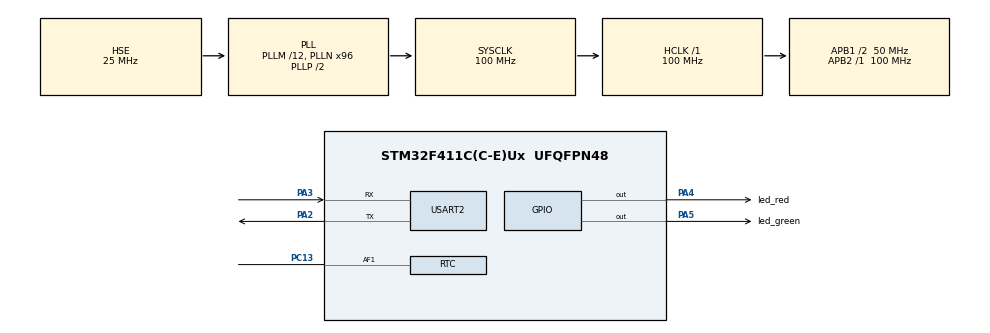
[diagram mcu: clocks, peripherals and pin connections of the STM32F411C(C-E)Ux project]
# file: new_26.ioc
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Dma.Request0=USART2_RX
Dma.Request1=USART2_TX
Dma.USART2_RX.0.Direction=DMA_PERIPH_TO_MEMORY
Dma.USART2_RX.0.FIFOMode=DMA_FIFOMODE_DISABLE
Dma.USART2_RX.0.Instance=DMA1_Stream5
Dma.USART2_RX.0.MemDataAlignment=DMA_MDATAALIGN_BYTE
Dma.USART2_RX.0.MemInc=DMA_MINC_ENABLE
Dma.USART2_RX.0.Mode=DMA_CIRCULAR
Dma.USART2_RX.0.PeriphDataAlignment=DMA_PDATAALIGN_BYTE
Dma.USART2_RX.0.PeriphInc=DMA_PINC_DISABLE
Dma.USART2_RX.0.Priority=DMA_PRIORITY_MEDIUM
Dma.USART2_TX.1.Direction=DMA_MEMORY_TO_PERIPH
Dma.USART2_TX.1.FIFOMode=DMA_FIFOMODE_DISABLE
Dma.USART2_TX.1.Instance=DMA1_Stream6
Dma.USART2_TX.1.MemDataAlignment=DMA_MDATAALIGN_BYTE
Dma.USART2_TX.1.MemInc=DMA_MINC_ENABLE
Dma.USART2_TX.1.Mode=DMA_NORMAL
Dma.USART2_TX.1.PeriphDataAlignment=DMA_PDATAALIGN_BYTE
Dma.USART2_TX.1.PeriphInc=DMA_PINC_DISABLE
Dma.USART2_TX.1.Priority=DMA_PRIORITY_LOW
FREERTOS.Queues01=queue_input_uart,10,uint16_t,0,Dynamic,NULL,NULL;queue_uart_output,10,uint16_t,0,Dynamic,NULL,NULL;queue_output_input,10,uint16_t,0,Dynamic,NULL,NULL
FREERTOS.Tasks01=task_input,24,128,start_task_input,Default,NULL,Dynamic,NULL,NULL;task_uart,16,128,start_task_uart,Default,NULL,Dynamic,NULL,NULL;task_output,16,128,start_task_output,Default,NULL,Dynamic,NULL,NULL
Mcu.Family=STM32F4
Mcu.Name=STM32F411C(C-E)Ux
Mcu.Package=UFQFPN48
NVIC.DMA1_Stream5_IRQn=true\:7\:0\:true\:false\:true\:true\:false\:true\:true
NVIC.DMA1_Stream6_IRQn=true\:7\:0\:true\:false\:true\:true\:false\:true\:true
NVIC.PriorityGroup=NVIC_PRIORITYGROUP_4
NVIC.RTC_WKUP_IRQn=true\:6\:0\:true\:false\:true\:true\:true\:true\:true
NVIC.TIM4_IRQn=true\:15\:0\:false\:false\:true\:false\:false\:true\:true
NVIC.TimeBase=TIM4_IRQn
NVIC.TimeBaseIP=TIM4
NVIC.USART2_IRQn=true\:6\:0\:true\:false\:true\:true\:true\:true\:true
PA13.Mode=Serial_Wire
PA13.Signal=SYS_JTMS-SWDIO
PA14.Mode=Serial_Wire
PA14.Signal=SYS_JTCK-SWCLK
PA2.Mode=Asynchronous
PA2.Signal=USART2_TX
PA3.Mode=Asynchronous
PA3.Signal=USART2_RX
PA4.GPIO_Label=led_red
PA4.GPIO_Speed=GPIO_SPEED_FREQ_VERY_HIGH
PA4.Signal=GPIO_Output
PA5.GPIO_Label=led_green
PA5.GPIO_Speed=GPIO_SPEED_FREQ_VERY_HIGH
PA5.Signal=GPIO_Output
PC13-ANTI_TAMP.Mode=WakeUpAF1
PC13-ANTI_TAMP.Signal=RTC_AF1
PC14-OSC32_IN.Mode=LSE-External-Oscillator
PC14-OSC32_IN.Signal=RCC_OSC32_IN
PC15-OSC32_OUT.Mode=LSE-External-Oscillator
PC15-OSC32_OUT.Signal=RCC_OSC32_OUT
PH0\ -\ OSC_IN.Mode=HSE-External-Oscillator
PH0\ -\ OSC_IN.Signal=RCC_OSC_IN
PH1\ -\ OSC_OUT.Mode=HSE-External-Oscillator
PH1\ -\ OSC_OUT.Signal=RCC_OSC_OUT
ProjectManager.HeapSize=0x200
ProjectManager.StackSize=0x400
ProjectManager.TargetToolchain=STM32CubeIDE
RCC.48MHZClocksFreq_Value=50000000
RCC.AHBFreq_Value=100000000
RCC.APB1CLKDivider=RCC_HCLK_DIV2
RCC.APB1Freq_Value=50000000
RCC.APB1TimFreq_Value=100000000
RCC.APB2Freq_Value=100000000
RCC.APB2TimFreq_Value=100000000
RCC.CortexFreq_Value=100000000
RCC.HCLKFreq_Value=100000000
RCC.HSE_VALUE=25000000
RCC.HSI_VALUE=16000000
RCC.PLLM=12
RCC.PLLN=96
RCC.PLLSourceVirtual=RCC_PLLSOURCE_HSE
RCC.SYSCLKFreq_VALUE=100000000
RCC.SYSCLKSource=RCC_SYSCLKSOURCE_PLLCLK
RCC.VCOOutputFreq_Value=200000000
RTC.Format=RTC_FORMAT_BIN
RTC.OutPutPolarity=RTC_OUTPUT_POLARITY_LOW
RTC.WakeUpClock=RTC_WAKEUPCLOCK_CK_SPRE_16BITS
USART2.VirtualMode=VM_ASYNC
VP_FREERTOS_VS_CMSIS_V2.Mode=CMSIS_V2
VP_RTC_VS_RTC_Activate.Mode=RTC_Enabled
VP_SYS_VS_tim4.Mode=TIM4
board=custom

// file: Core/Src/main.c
/* USER CODE BEGIN Header */
/**
  ******************************************************************************
  * @file           : main.c
  * @brief          : Main program body
  ******************************************************************************
  * @attention
  *
  * Copyright (c) 2024 STMicroelectronics.
  * All rights reserved.
  *
  * This software is licensed under terms that can be found in the LICENSE file
  * in the root directory of this software component.
  * If no LICENSE file comes with this software, it is provided AS-IS.
  *
  ******************************************************************************
  */
/* USER CODE END Header */
#include "main.h"
#include "cmsis_os.h"
#include "dma.h"
#include "rtc.h"
#include "usart.h"
#include "gpio.h"

void SystemClock_Config(void);
void MX_FREERTOS_Init(void);

int main(void)
{

  /* MCU Configuration--------------------------------------------------------*/

  /* Reset of all peripherals, Initializes the Flash interface and the Systick. */
  HAL_Init();

  /* Configure the system clock */
  SystemClock_Config();

  /* Initialize all configured peripherals */
  MX_GPIO_Init();
  MX_DMA_Init();
  MX_USART2_UART_Init();
  MX_RTC_Init();

  /* Init scheduler */
  osKernelInitialize();

  /* Call init function for freertos objects (in cmsis_os2.c) */
  MX_FREERTOS_Init();

  /* Start scheduler */
  osKernelStart();

  /* We should never get here as control is now taken by the scheduler */

  /* Infinite loop */
  while (1)
  {

  }
}

void SystemClock_Config(void)
{
  RCC_OscInitTypeDef RCC_OscInitStruct = {0};
  RCC_ClkInitTypeDef RCC_ClkInitStruct = {0};

  /** Configure the main internal regulator output voltage
  */
  __HAL_RCC_PWR_CLK_ENABLE();
  __HAL_PWR_VOLTAGESCALING_CONFIG(PWR_REGULATOR_VOLTAGE_SCALE1);

  /** Initializes the RCC Oscillators according to the specified parameters
  * in the RCC_OscInitTypeDef structure.
  */
  RCC_OscInitStruct.OscillatorType = RCC_OSCILLATORTYPE_LSI|RCC_OSCILLATORTYPE_HSE;
  RCC_OscInitStruct.HSEState = RCC_HSE_ON;
  RCC_OscInitStruct.LSIState = RCC_LSI_ON;
  RCC_OscInitStruct.PLL.PLLState = RCC_PLL_ON;
  RCC_OscInitStruct.PLL.PLLSource = RCC_PLLSOURCE_HSE;
  RCC_OscInitStruct.PLL.PLLM = 12;
  RCC_OscInitStruct.PLL.PLLN = 96;
  RCC_OscInitStruct.PLL.PLLP = RCC_PLLP_DIV2;
  RCC_OscInitStruct.PLL.PLLQ = 4;
  if (HAL_RCC_OscConfig(&RCC_OscInitStruct) != HAL_OK)
  {
    Error_Handler();
  }

  /** Initializes the CPU, AHB and APB buses clocks
  */
  RCC_ClkInitStruct.ClockType = RCC_CLOCKTYPE_HCLK|RCC_CLOCKTYPE_SYSCLK
                              |RCC_CLOCKTYPE_PCLK1|RCC_CLOCKTYPE_PCLK2;
  RCC_ClkInitStruct.SYSCLKSource = RCC_SYSCLKSOURCE_PLLCLK;
  RCC_ClkInitStruct.AHBCLKDivider = RCC_SYSCLK_DIV1;
  RCC_ClkInitStruct.APB1CLKDivider = RCC_HCLK_DIV2;
  RCC_ClkInitStruct.APB2CLKDivider = RCC_HCLK_DIV1;

  if (HAL_RCC_ClockConfig(&RCC_ClkInitStruct, FLASH_LATENCY_3) != HAL_OK)
  {
    Error_Handler();
  }
}

void HAL_TIM_PeriodElapsedCallback(TIM_HandleTypeDef *htim)
{
  if (htim->Instance == TIM4) {
    HAL_IncTick();
  }
}

void Error_Handler(void)
{
  __disable_irq();
  while (1)
  {
  }
}

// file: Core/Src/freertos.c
/* USER CODE BEGIN Header */
/**
  ******************************************************************************
  * File Name          : freertos.c
  * Description        : Code for freertos applications
  ******************************************************************************
  * @attention
  *
  * Copyright (c) 2024 STMicroelectronics.
  * All rights reserved.
  *
  * This software is licensed under terms that can be found in the LICENSE file
  * in the root directory of this software component.
  * If no LICENSE file comes with this software, it is provided AS-IS.
  *
  ******************************************************************************
  */
/* USER CODE END Header */

/* USER CODE BEGIN Includes */
#include "self.h"
/* USER CODE END Includes */

/* USER CODE BEGIN Variables */
char rx_buffer[20];
/* USER CODE END Variables */
/* Definitions for task_input */
osThreadId_t task_inputHandle;
const osThreadAttr_t task_input_attributes = {
  .name = "task_input",
  .stack_size = 128 * 4,
  .priority = (osPriority_t) osPriorityNormal,
};
/* Definitions for task_uart */
osThreadId_t task_uartHandle;
const osThreadAttr_t task_uart_attributes = {
  .name = "task_uart",
  .stack_size = 128 * 4,
  .priority = (osPriority_t) osPriorityBelowNormal,
};
/* Definitions for task_output */
osThreadId_t task_outputHandle;
const osThreadAttr_t task_output_attributes = {
  .name = "task_output",
  .stack_size = 128 * 4,
  .priority = (osPriority_t) osPriorityBelowNormal,
};
/* Definitions for queue_input_uart */
osMessageQueueId_t queue_input_uartHandle;
const osMessageQueueAttr_t queue_input_uart_attributes = {
  .name = "queue_input_uart"
};
/* Definitions for queue_uart_output */
osMessageQueueId_t queue_uart_outputHandle;
const osMessageQueueAttr_t queue_uart_output_attributes = {
  .name = "queue_uart_output"
};
/* Definitions for queue_output_input */
osMessageQueueId_t queue_output_inputHandle;
const osMessageQueueAttr_t queue_output_input_attributes = {
  .name = "queue_output_input"
};

void start_task_input(void *argument);
void start_task_uart(void *argument);
void start_task_output(void *argument);

void MX_FREERTOS_Init(void); /* (MISRA C 2004 rule 8.1) */

void MX_FREERTOS_Init(void) {

  /* Create the queue(s) */
  /* creation of queue_input_uart */
  queue_input_uartHandle = osMessageQueueNew (10, sizeof(uint16_t), &queue_input_uart_attributes);

  /* creation of queue_uart_output */
  queue_uart_outputHandle = osMessageQueueNew (10, sizeof(uint16_t), &queue_uart_output_attributes);

  /* creation of queue_output_input */
  queue_output_inputHandle = osMessageQueueNew (10, sizeof(uint16_t), &queue_output_input_attributes);

  /* Create the thread(s) */
  /* creation of task_input */
  task_inputHandle = osThreadNew(start_task_input, NULL, &task_input_attributes);

  /* creation of task_uart */
  task_uartHandle = osThreadNew(start_task_uart, NULL, &task_uart_attributes);

  /* creation of task_output */
  task_outputHandle = osThreadNew(start_task_output, NULL, &task_output_attributes);

}

void start_task_input(void *argument)
{
  /* USER CODE BEGIN start_task_input */
  /* Infinite loop */
  for(;;)
  {
    vTaskDelay(1000);
  }
  /* USER CODE END start_task_input */
}

void start_task_uart(void *argument)
{
  /* USER CODE BEGIN start_task_uart */
  __HAL_UART_DISABLE_IT(&huart2, UART_IT_TC);
  __HAL_UART_DISABLE_IT(&huart2, UART_IT_RXNE);
  HAL_UART_Transmit_DMA(&huart2, (uint8_t *)"start\r\n", strlen("start\r\n"));

  /* Infinite loop */
  for(;;)
  {
    HAL_UART_Receive_DMA(&huart2, (uint8_t *)rx_buffer, 20);
    //format eample: #2024_11_24 09:56:33;
    vTaskDelay(20);
  }
  /* USER CODE END start_task_uart */
}

void start_task_output(void *argument)
{
  /* USER CODE BEGIN start_task_output */
  /* Infinite loop */
  for(;;)
  {
    vTaskDelay(3000);
  }
  /* USER CODE END start_task_output */
}
